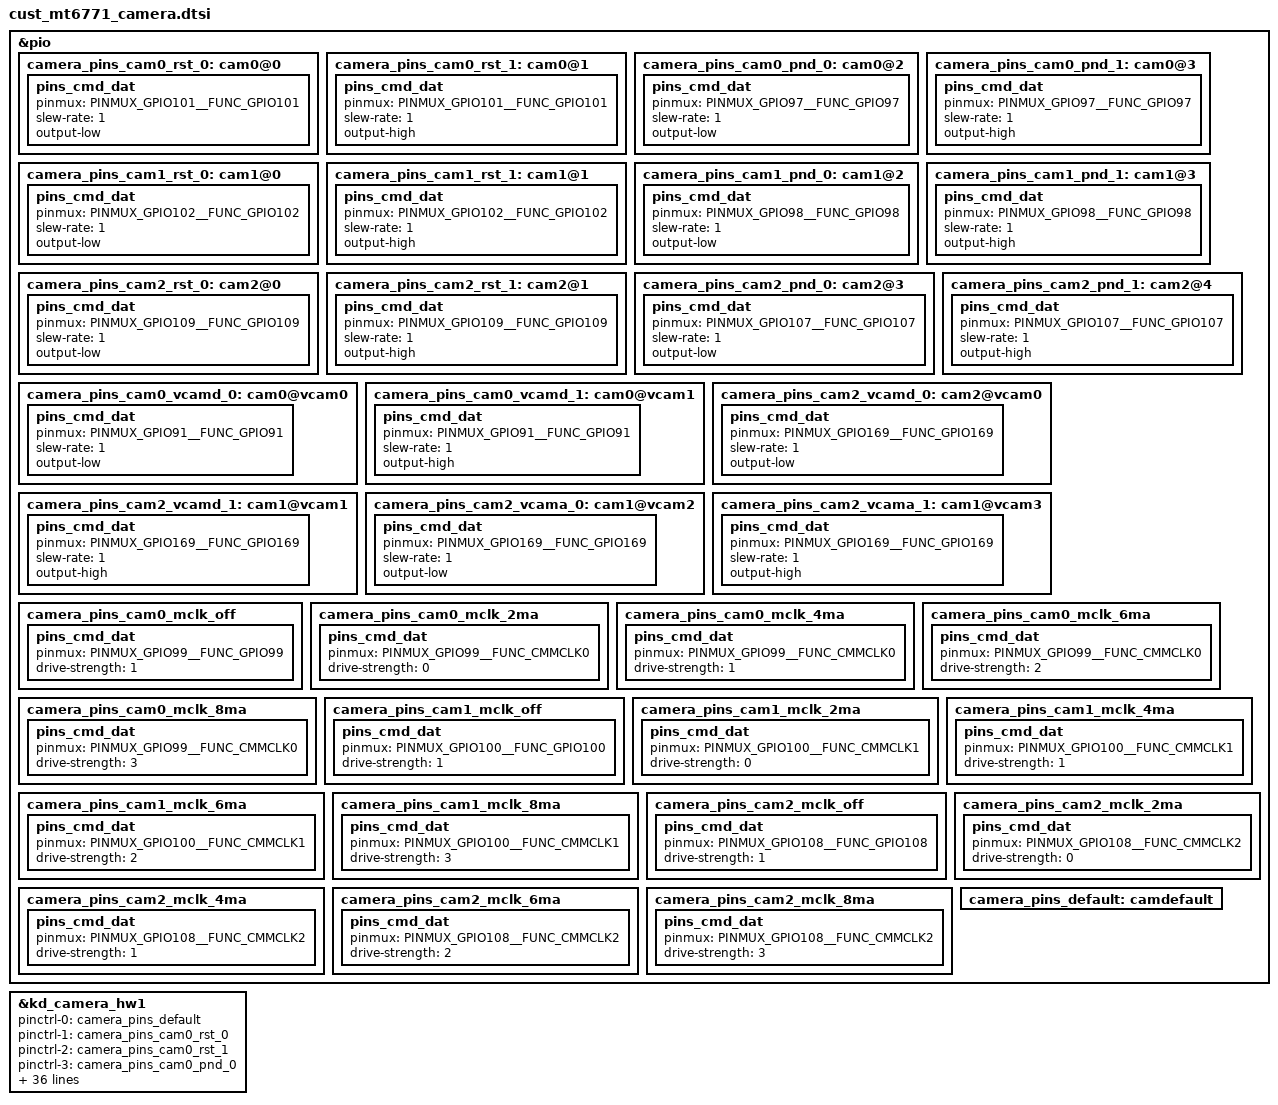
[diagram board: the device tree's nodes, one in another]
/*
 * Copyright (c) 2019 MediaTek Inc.
 *
 * This program is free software; you can redistribute it and/or modify
 * it under the terms of the GNU General Public License version 2 as
 * published by the Free Software Foundation.
 *
 * This program is distributed in the hope that it will be useful,
 * but WITHOUT ANY WARRANTY; without even the implied warranty of
 * MERCHANTABILITY or FITNESS FOR A PARTICULAR PURPOSE.  See the
 * GNU General Public License for more details.
 */
/* CAMERA GPIO standardization */
&pio {
	camera_pins_cam0_rst_0: cam0@0 {
		pins_cmd_dat {
			pinmux = <PINMUX_GPIO101__FUNC_GPIO101>;
			slew-rate = <1>;
			output-low;
		};
	};
	camera_pins_cam0_rst_1: cam0@1 {
		pins_cmd_dat {
			pinmux = <PINMUX_GPIO101__FUNC_GPIO101>;
			slew-rate = <1>;
			output-high;
		};
	};
	camera_pins_cam0_pnd_0: cam0@2 {
		pins_cmd_dat {
			pinmux = <PINMUX_GPIO97__FUNC_GPIO97>;
			slew-rate = <1>;
			output-low;
		};
	};
	camera_pins_cam0_pnd_1: cam0@3 {
		pins_cmd_dat {
			pinmux = <PINMUX_GPIO97__FUNC_GPIO97>;
			slew-rate = <1>;
			output-high;
		};
	};
	camera_pins_cam1_rst_0: cam1@0 {
		pins_cmd_dat {
			pinmux = <PINMUX_GPIO102__FUNC_GPIO102>;
			slew-rate = <1>;
			output-low;
		};
	};
	camera_pins_cam1_rst_1: cam1@1 {
		pins_cmd_dat {
			pinmux = <PINMUX_GPIO102__FUNC_GPIO102>;
			slew-rate = <1>;
			output-high;
		};
	};
	camera_pins_cam1_pnd_0: cam1@2 {
		pins_cmd_dat {
			pinmux = <PINMUX_GPIO98__FUNC_GPIO98>;
			slew-rate = <1>;
			output-low;
		};
	};
	camera_pins_cam1_pnd_1: cam1@3 {
		pins_cmd_dat {
			pinmux = <PINMUX_GPIO98__FUNC_GPIO98>;
			slew-rate = <1>;
			output-high;
		};
	};
	camera_pins_cam2_rst_0: cam2@0 {
		pins_cmd_dat {
			pinmux = <PINMUX_GPIO109__FUNC_GPIO109>;
			slew-rate = <1>;
			output-low;
		};
	};
	camera_pins_cam2_rst_1: cam2@1 {
		pins_cmd_dat {
			pinmux = <PINMUX_GPIO109__FUNC_GPIO109>;
			slew-rate = <1>;
			output-high;
		};
	};
	camera_pins_cam2_pnd_0: cam2@3 {
		pins_cmd_dat {
			pinmux = <PINMUX_GPIO107__FUNC_GPIO107>;
			slew-rate = <1>;
			output-low;
		};
	};
	camera_pins_cam2_pnd_1: cam2@4 {
		pins_cmd_dat {
			pinmux = <PINMUX_GPIO107__FUNC_GPIO107>;
			slew-rate = <1>;
			output-high;
		};
	};
	camera_pins_cam0_vcamd_0: cam0@vcam0 {
		pins_cmd_dat {
			pinmux = <PINMUX_GPIO91__FUNC_GPIO91>;
			slew-rate = <1>;
			output-low;
		};
	};
	camera_pins_cam0_vcamd_1: cam0@vcam1 {
		pins_cmd_dat {
			pinmux = <PINMUX_GPIO91__FUNC_GPIO91>;
			slew-rate = <1>;
			output-high;
		};
	};
	camera_pins_cam2_vcamd_0: cam2@vcam0 {
		pins_cmd_dat {
			pinmux = <PINMUX_GPIO169__FUNC_GPIO169>;
			slew-rate = <1>;
			output-low;
		};
	};
	camera_pins_cam2_vcamd_1: cam1@vcam1 {
		pins_cmd_dat {
			pinmux = <PINMUX_GPIO169__FUNC_GPIO169>;
			slew-rate = <1>;
			output-high;
		};
	};
	camera_pins_cam2_vcama_0: cam1@vcam2 {
		pins_cmd_dat {
			pinmux = <PINMUX_GPIO169__FUNC_GPIO169>;
			slew-rate = <1>;
			output-low;
		};
	};
	camera_pins_cam2_vcama_1: cam1@vcam3 {
		pins_cmd_dat {
			pinmux = <PINMUX_GPIO169__FUNC_GPIO169>;
			slew-rate = <1>;
			output-high;
		};
	};
	camera_pins_cam0_mclk_off: camera_pins_cam0_mclk_off {
		pins_cmd_dat {
			pinmux = <PINMUX_GPIO99__FUNC_GPIO99>;
			drive-strength = <1>;
		};
	};
	camera_pins_cam0_mclk_2ma: camera_pins_cam0_mclk_2ma {
		pins_cmd_dat {
			pinmux = <PINMUX_GPIO99__FUNC_CMMCLK0>;
			drive-strength = <0>;
		};
	};
	camera_pins_cam0_mclk_4ma: camera_pins_cam0_mclk_4ma {
		pins_cmd_dat {
			pinmux = <PINMUX_GPIO99__FUNC_CMMCLK0>;
			drive-strength = <1>;
		};
	};
	camera_pins_cam0_mclk_6ma: camera_pins_cam0_mclk_6ma {
		pins_cmd_dat {
			pinmux = <PINMUX_GPIO99__FUNC_CMMCLK0>;
			drive-strength = <2>;
		};
	};
	camera_pins_cam0_mclk_8ma: camera_pins_cam0_mclk_8ma {
		pins_cmd_dat {
			pinmux = <PINMUX_GPIO99__FUNC_CMMCLK0>;
			drive-strength = <3>;
		};
	};
	camera_pins_cam1_mclk_off: camera_pins_cam1_mclk_off {
		pins_cmd_dat {
			pinmux = <PINMUX_GPIO100__FUNC_GPIO100>;
			drive-strength = <1>;
		};
	};
	camera_pins_cam1_mclk_2ma: camera_pins_cam1_mclk_2ma {
		pins_cmd_dat {
			pinmux = <PINMUX_GPIO100__FUNC_CMMCLK1>;
			drive-strength = <0>;
		};
	};
	camera_pins_cam1_mclk_4ma: camera_pins_cam1_mclk_4ma {
		pins_cmd_dat {
			pinmux = <PINMUX_GPIO100__FUNC_CMMCLK1>;
			drive-strength = <1>;
		};
	};
	camera_pins_cam1_mclk_6ma: camera_pins_cam1_mclk_6ma {
		pins_cmd_dat {
			pinmux = <PINMUX_GPIO100__FUNC_CMMCLK1>;
			drive-strength = <2>;
		};
	};
	camera_pins_cam1_mclk_8ma: camera_pins_cam1_mclk_8ma {
		pins_cmd_dat {
			pinmux = <PINMUX_GPIO100__FUNC_CMMCLK1>;
			drive-strength = <3>;
		};
	};
	camera_pins_cam2_mclk_off: camera_pins_cam2_mclk_off {
		pins_cmd_dat {
			pinmux = <PINMUX_GPIO108__FUNC_GPIO108>;
			drive-strength = <1>;
		};
	};
	camera_pins_cam2_mclk_2ma: camera_pins_cam2_mclk_2ma {
		pins_cmd_dat {
			pinmux = <PINMUX_GPIO108__FUNC_CMMCLK2>;
			drive-strength = <0>;
		};
	};
	camera_pins_cam2_mclk_4ma: camera_pins_cam2_mclk_4ma {
		pins_cmd_dat {
			pinmux = <PINMUX_GPIO108__FUNC_CMMCLK2>;
			drive-strength = <1>;
		};
	};
	camera_pins_cam2_mclk_6ma: camera_pins_cam2_mclk_6ma {
		pins_cmd_dat {
			pinmux = <PINMUX_GPIO108__FUNC_CMMCLK2>;
			drive-strength = <2>;
		};
	};
	camera_pins_cam2_mclk_8ma: camera_pins_cam2_mclk_8ma {
		pins_cmd_dat {
			pinmux = <PINMUX_GPIO108__FUNC_CMMCLK2>;
			drive-strength = <3>;
		};
	};
	camera_pins_default: camdefault {
	};
};
&kd_camera_hw1 {
	pinctrl-names = "default",
			"cam0_rst0", "cam0_rst1",
			"cam0_pnd0", "cam0_pnd1",
			"cam1_rst0", "cam1_rst1",
			"cam1_pnd0", "cam1_pnd1",
			"cam2_rst0", "cam2_rst1",
			"cam2_pnd0", "cam2_pnd1",
			"cam0_ldo_vcamd_0", "cam0_ldo_vcamd_1",
			"cam2_ldo_vcamd_0", "cam2_ldo_vcamd_1",
			"cam2_ldo_vcama_0", "cam2_ldo_vcama_1",
			"cam0_mclk_off",
			"cam0_mclk_2mA", "cam0_mclk_4mA",
			"cam0_mclk_6mA", "cam0_mclk_8mA",
			"cam1_mclk_off",
			"cam1_mclk_2mA", "cam1_mclk_4mA",
			"cam1_mclk_6mA", "cam1_mclk_8mA",
			"cam2_mclk_off",
			"cam2_mclk_2mA", "cam2_mclk_4mA",
			"cam2_mclk_6mA", "cam2_mclk_8mA";
	pinctrl-0 = <&camera_pins_default>;
	pinctrl-1 = <&camera_pins_cam0_rst_0>;
	pinctrl-2 = <&camera_pins_cam0_rst_1>;
	pinctrl-3 = <&camera_pins_cam0_pnd_0>;
	pinctrl-4 = <&camera_pins_cam0_pnd_1>;
	pinctrl-5 = <&camera_pins_cam1_rst_0>;
	pinctrl-6 = <&camera_pins_cam1_rst_1>;
	pinctrl-7 = <&camera_pins_cam1_pnd_0>;
	pinctrl-8 = <&camera_pins_cam1_pnd_1>;
	pinctrl-9 = <&camera_pins_cam2_rst_0>;
	pinctrl-10 = <&camera_pins_cam2_rst_1>;
	pinctrl-11 = <&camera_pins_cam2_pnd_0>;
	pinctrl-12 = <&camera_pins_cam2_pnd_1>;
	pinctrl-13 = <&camera_pins_cam0_vcamd_0>;
	pinctrl-14 = <&camera_pins_cam0_vcamd_1>;
	pinctrl-15 = <&camera_pins_cam2_vcamd_0>;
	pinctrl-16 = <&camera_pins_cam2_vcamd_1>;
	pinctrl-17 = <&camera_pins_cam2_vcama_0>;
	pinctrl-18 = <&camera_pins_cam2_vcama_1>;
	pinctrl-19 = <&camera_pins_cam0_mclk_off>;
	pinctrl-20 = <&camera_pins_cam0_mclk_2ma>;
	pinctrl-21 = <&camera_pins_cam0_mclk_4ma>;
	pinctrl-22 = <&camera_pins_cam0_mclk_6ma>;
	pinctrl-23 = <&camera_pins_cam0_mclk_8ma>;
	pinctrl-24 = <&camera_pins_cam1_mclk_off>;
	pinctrl-25 = <&camera_pins_cam1_mclk_2ma>;
	pinctrl-26 = <&camera_pins_cam1_mclk_4ma>;
	pinctrl-27 = <&camera_pins_cam1_mclk_6ma>;
	pinctrl-28 = <&camera_pins_cam1_mclk_8ma>;
	pinctrl-29 = <&camera_pins_cam2_mclk_off>;
	pinctrl-30 = <&camera_pins_cam2_mclk_2ma>;
	pinctrl-31 = <&camera_pins_cam2_mclk_4ma>;
	pinctrl-32 = <&camera_pins_cam2_mclk_6ma>;
	pinctrl-33 = <&camera_pins_cam2_mclk_8ma>;

	cam0_vcama-supply = <&mt_pmic_vcama2_ldo_reg>;
	cam0_vcamio-supply = <&mt_pmic_vcamio_ldo_reg>;
	cam1_vcama-supply = <&mt_pmic_vcama1_ldo_reg>;
	cam1_vcamd-supply = <&mt_pmic_vcamd_ldo_reg>;
	cam1_vcamio-supply = <&mt_pmic_vcamio_ldo_reg>;
	cam2_vcamio-supply = <&mt_pmic_vcamio_ldo_reg>;

	status = "okay";
};
/* CAMERA GPIO end */
